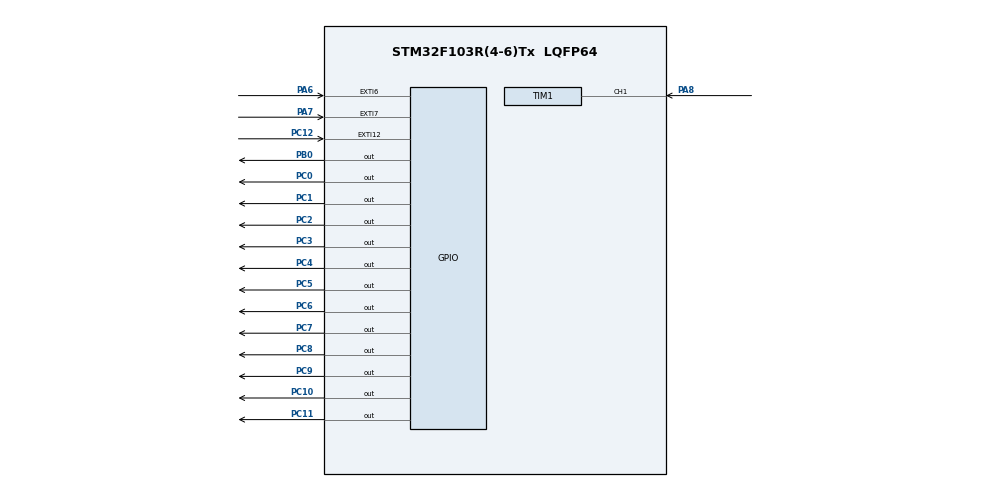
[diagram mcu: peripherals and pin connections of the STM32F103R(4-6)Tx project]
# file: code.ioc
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Mcu.Family=STM32F1
PC10.GPIO_PuPd=GPIO_PULLUP
PC10.Signal=GPIO_Output
PC12.Signal=GPXTI12
PC0.GPIO_ModeDefaultOutputPP=GPIO_MODE_OUTPUT_PP
NVIC.TIM1_UP_IRQn=true\:1\:0\:true\:false\:true\:true\:true
ProjectManager.StackSize=0x400
PC3.PinState=GPIO_PIN_RESET
PC8.PinState=GPIO_PIN_RESET
PC11.GPIO_PuPd=GPIO_PULLUP
TIM1.Prescaler=999
PB0.PinState=GPIO_PIN_RESET
PC7.Signal=GPIO_Output
PC3.Signal=GPIO_Output
PC1.PinState=GPIO_PIN_RESET
NVIC.EXTI15_10_IRQn=true\:0\:0\:false\:false\:true\:true\:true
PC1.GPIO_PuPd=GPIO_PULLUP
PC7.PinState=GPIO_PIN_RESET
PA8.Signal=S_TIM1_CH1
PC10.PinState=GPIO_PIN_RESET
VP_TIM1_VS_ClockSourceINT.Mode=Internal
PC10.GPIO_ModeDefaultOutputPP=GPIO_MODE_OUTPUT_PP
Mcu.Package=LQFP64
PA6.Signal=GPXTI6
PC8.GPIO_ModeDefaultOutputPP=GPIO_MODE_OUTPUT_PP
PC6.GPIO_PuPd=GPIO_PULLUP
PC2.GPIO_ModeDefaultOutputPP=GPIO_MODE_OUTPUT_PP
PB0.GPIO_ModeDefaultOutputPP=GPIO_MODE_OUTPUT_PP
PC5.Signal=GPIO_Output
TIM1.Period=79
PC0.GPIO_PuPd=GPIO_PULLUP
PC4.GPIO_ModeDefaultOutputPP=GPIO_MODE_OUTPUT_PP
PC0.PinState=GPIO_PIN_RESET
PC6.GPIO_ModeDefaultOutputPP=GPIO_MODE_OUTPUT_PP
PC7.GPIO_ModeDefaultOutputPP=GPIO_MODE_OUTPUT_PP
PC4.PinState=GPIO_PIN_RESET
PC4.GPIO_PuPd=GPIO_PULLUP
PC11.Signal=GPIO_Output
PA7.GPIO_ModeDefaultEXTI=GPIO_MODE_IT_FALLING
PC8.Signal=GPIO_Output
PC2.Signal=GPIO_Output
PC4.Signal=GPIO_Output
PC6.Signal=GPIO_Output
PC9.PinState=GPIO_PIN_RESET
PC0.Signal=GPIO_Output
PC5.GPIO_PuPd=GPIO_PULLUP
VP_SYS_VS_ND.Mode=No_Debug
SH.S_TIM1_CH1.0=TIM1_CH1,Input_Capture1_from_TI1
ProjectManager.TargetToolchain=Makefile
PC7.GPIO_PuPd=GPIO_PULLUP
PC6.PinState=GPIO_PIN_RESET
board=custom
RCC.APB2Freq_Value=8000000
PC11.PinState=GPIO_PIN_RESET
PC9.GPIO_ModeDefaultOutputPP=GPIO_MODE_OUTPUT_PP
PC9.GPIO_PuPd=GPIO_PULLUP
PC2.GPIO_PuPd=GPIO_PULLUP
PC11.GPIO_ModeDefaultOutputPP=GPIO_MODE_OUTPUT_PP
Mcu.Name=STM32F103R(4-6)Tx
NVIC.TIM1_CC_IRQn=true\:0\:0\:false\:false\:true\:true\:true
PC8.GPIO_PuPd=GPIO_PULLUP
PC2.PinState=GPIO_PIN_RESET
PC5.PinState=GPIO_PIN_RESET
TIM1.Channel-Input_Capture1_from_TI1=TIM_CHANNEL_1
NVIC.EXTI9_5_IRQn=true\:0\:0\:false\:false\:true\:true\:true
ProjectManager.HeapSize=0x200
PC1.GPIO_ModeDefaultOutputPP=GPIO_MODE_OUTPUT_PP
NVIC.PriorityGroup=NVIC_PRIORITYGROUP_4
PC9.Signal=GPIO_Output
PC3.GPIO_ModeDefaultOutputPP=GPIO_MODE_OUTPUT_PP
RCC.APB1Freq_Value=8000000
PC5.GPIO_ModeDefaultOutputPP=GPIO_MODE_OUTPUT_PP
PB0.Signal=GPIO_Output
PC1.Signal=GPIO_Output
PB0.GPIO_PuPd=GPIO_PULLUP
PC3.GPIO_PuPd=GPIO_PULLUP
PA7.Signal=GPXTI7

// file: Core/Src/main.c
/* USER CODE BEGIN Header */
/**
  ******************************************************************************
  * @file           : main.c
  * @brief          : Main program body
  ******************************************************************************
  * @attention
  *
  * <h2><center>&copy; Copyright (c) 2020 STMicroelectronics.
  * All rights reserved.</center></h2>
  *
  * This software component is licensed by ST under BSD 3-Clause license,
  * the "License"; You may not use this file except in compliance with the
  * License. You may obtain a copy of the License at:
  *                        opensource.org/licenses/BSD-3-Clause
  *
  ******************************************************************************
  */
/* USER CODE END Header */
#include "main.h"
#include "tim.h"
#include "gpio.h"

void SystemClock_Config(void);

int main(void)
{

  /* MCU Configuration--------------------------------------------------------*/

  /* Reset of all peripherals, Initializes the Flash interface and the Systick. */
  HAL_Init();

  /* Configure the system clock */
  SystemClock_Config();

  /* Initialize all configured peripherals */
  MX_GPIO_Init();
  MX_TIM1_Init();
  /* USER CODE BEGIN 2 */

  HAL_TIM_Base_Start_IT(&htim1);
  HAL_TIM_IC_Start_IT(&htim1, TIM_CHANNEL_1);

  casovnik();

  /* USER CODE END 2 */

  /* Infinite loop */
  while (1)
  {

  }
}

void SystemClock_Config(void)
{
  RCC_OscInitTypeDef RCC_OscInitStruct = {0};
  RCC_ClkInitTypeDef RCC_ClkInitStruct = {0};

  /** Initializes the RCC Oscillators according to the specified parameters
  * in the RCC_OscInitTypeDef structure.
  */
  RCC_OscInitStruct.OscillatorType = RCC_OSCILLATORTYPE_HSI;
  RCC_OscInitStruct.HSIState = RCC_HSI_ON;
  RCC_OscInitStruct.HSICalibrationValue = RCC_HSICALIBRATION_DEFAULT;
  RCC_OscInitStruct.PLL.PLLState = RCC_PLL_NONE;
  if (HAL_RCC_OscConfig(&RCC_OscInitStruct) != HAL_OK)
  {
    Error_Handler();
  }
  /** Initializes the CPU, AHB and APB buses clocks
  */
  RCC_ClkInitStruct.ClockType = RCC_CLOCKTYPE_HCLK|RCC_CLOCKTYPE_SYSCLK
                              |RCC_CLOCKTYPE_PCLK1|RCC_CLOCKTYPE_PCLK2;
  RCC_ClkInitStruct.SYSCLKSource = RCC_SYSCLKSOURCE_HSI;
  RCC_ClkInitStruct.AHBCLKDivider = RCC_SYSCLK_DIV1;
  RCC_ClkInitStruct.APB1CLKDivider = RCC_HCLK_DIV1;
  RCC_ClkInitStruct.APB2CLKDivider = RCC_HCLK_DIV1;

  if (HAL_RCC_ClockConfig(&RCC_ClkInitStruct, FLASH_LATENCY_0) != HAL_OK)
  {
    Error_Handler();
  }
}

void Error_Handler(void)
{
}

/************************ (C) COPYRIGHT STMicroelectronics *****END OF FILE****/
